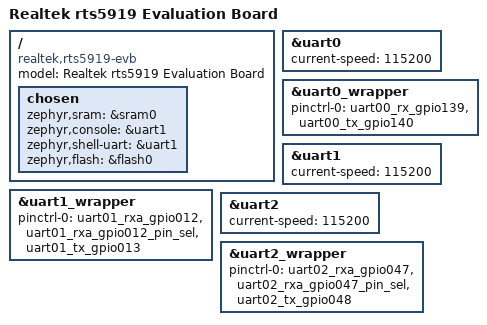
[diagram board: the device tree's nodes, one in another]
/*
 * SPDX-License-Identifier: Apache-2.0
 *
 * Copyright (c) 2024 Realtek Semiconductor Corporation, SIBG-SD7
 *
 */

/dts-v1/;
#include <realtek/ec/rts5919.dtsi>
#include <realtek/ec/rts5919-pinctrl.dtsi>
#include <zephyr/dt-bindings/gpio/gpio.h>

/ {
	model = "Realtek rts5919 Evaluation Board";
	compatible = "realtek,rts5919-evb";

	chosen {
		zephyr,sram = &sram0;
		zephyr,console = &uart1;
		zephyr,shell-uart = &uart1;
		zephyr,flash = &flash0;
	};
};

&uart0 {
	status = "okay";
	current-speed = <115200>;
};

&uart0_wrapper {
	status = "okay";
	pinctrl-0 = <&uart00_rx_gpio139 &uart00_tx_gpio140>;
	pinctrl-names = "default";
};

&uart1 {
	status = "okay";
	current-speed = <115200>;
};

&uart1_wrapper {
	status = "okay";
	pinctrl-0 = <&uart01_rxa_gpio012 &uart01_rxa_gpio012_pin_sel &uart01_tx_gpio013>;
	pinctrl-names = "default";
};

&uart2 {
	status = "okay";
	current-speed = <115200>;
};

&uart2_wrapper {
	status = "okay";
	pinctrl-0 = <&uart02_rxa_gpio047 &uart02_rxa_gpio047_pin_sel &uart02_tx_gpio048>;
	pinctrl-names = "default";
};
